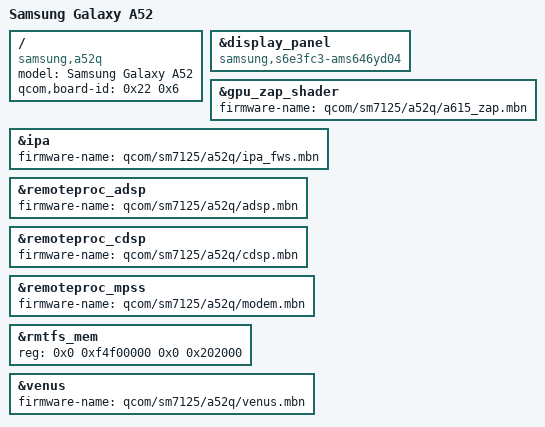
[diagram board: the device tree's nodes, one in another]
// SPDX-License-Identifier: GPL-2.0
/*
 * SM7125 Samsung Galaxy A52 (a52q) specific device tree source
 *
 * Copyright (c) 2026, Erikas Bitovtas. All rights reserved.
 */

/dts-v1/;

#include "sm7125-samsung-common.dtsi"

/ {
	model = "Samsung Galaxy A52";
	compatible = "samsung,a52q", "qcom,sm7125";
	qcom,board-id = <0x22 0x6>;
};

&display_panel {
	compatible = "samsung,s6e3fc3-ams646yd04", "samsung,s6e3fc3";

	status = "okay";
};

&gpu_zap_shader {
	firmware-name = "qcom/sm7125/a52q/a615_zap.mbn";
};

&ipa {
	firmware-name = "qcom/sm7125/a52q/ipa_fws.mbn";

	status = "okay";
};

&remoteproc_adsp {
	firmware-name = "qcom/sm7125/a52q/adsp.mbn";

	status = "okay";
};

&remoteproc_cdsp {
	firmware-name = "qcom/sm7125/a52q/cdsp.mbn";

	status = "okay";
};

&remoteproc_mpss {
	firmware-name = "qcom/sm7125/a52q/modem.mbn";

	status = "okay";
};

&rmtfs_mem {
	reg = <0x0 0xf4f00000 0x0 0x202000>;
};

&venus {
	firmware-name = "qcom/sm7125/a52q/venus.mbn";
};
